# STM32L053x register map
File version: 1.0
Registers are 32-bit, read-write, reset 0x0 unless marked. A register's access mark holds for its fields unless they carry their own. Offsets are from the block's base; [hi:lo] are bit positions; {n}, {i} and the like mark numbered series.

## IWDG — Independent watchdog
Base 0x40003000
0x00 KR wo — Key register
  [15:0] KEY — Key value (write only, read 0x0000)
0x04 PR — Prescaler register
  [2:0] PR — Prescaler divider
0x08 RLR reset 0xFFF — Reload register
  [11:0] RL — Watchdog counter reload value
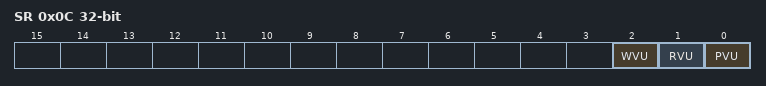
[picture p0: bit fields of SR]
0x0C SR ro — Status register
  [2] WVU — Watchdog counter window value update
  [1] RVU — Watchdog counter reload value update
  [0] PVU — Watchdog prescaler value update
0x10 WINR reset 0xFFF — Window register
  [11:0] WIN — Watchdog counter window value

## WWDG — System window watchdog
Base 0x40002C00
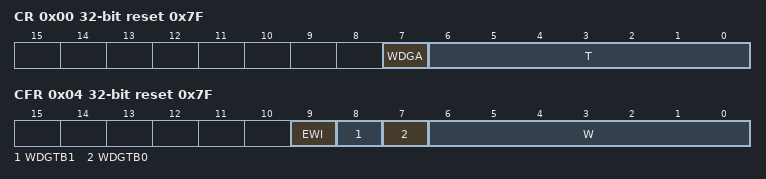
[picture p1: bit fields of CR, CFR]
0x00 CR reset 0x7F — Control register
  [7] WDGA — Activation bit
  [6:0] T — 7-bit counter (MSB to LSB)
0x04 CFR reset 0x7F — Configuration register
  [9] EWI — Early wakeup interrupt
  [8] WDGTB1 — Timer base
  [7] WDGTB0
  [6:0] W — 7-bit window value
0x08 SR rw-once — Status register
  [0] EWIF — Early wakeup interrupt flag

## COMP — Comparator
Base 0x40010018
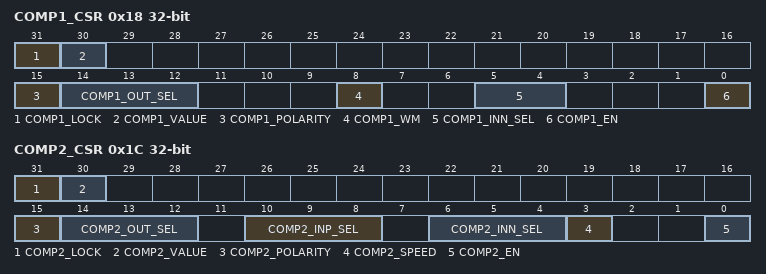
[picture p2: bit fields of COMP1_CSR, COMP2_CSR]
0x18 COMP1_CSR access per field — Comparator 1 control and status register
  [31] COMP1_LOCK wo — COMP1_CSR register lock bit
  [30] COMP1_VALUE ro — Comparator 1 output status bit
  [15] COMP1_POLARITY rw — Comparator 1 polarity selection bit
  [14:12] COMP1_OUT_SEL rw — COMP1 output select
  [8] COMP1_WM rw — Comparator 1 window mode selection bit
  [5:4] COMP1_INN_SEL rw — Comparator 1 Input Minus connection configuration bit
  [0] COMP1_EN rw — Comparator 1 enable bit
0x1C COMP2_CSR access per field — Comparator 2 control and status register
  [31] COMP2_LOCK wo — COMP2_CSR register lock bit
  [30] COMP2_VALUE ro — Comparator 2 output status bit
  [15] COMP2_POLARITY rw — Comparator 2 polarity selection bit
  [14:12] COMP2_OUT_SEL rw — COMP2 output select
  [10:8] COMP2_INP_SEL rw — Comparator 2 Input Plus connection configuration bit
  [6:4] COMP2_INN_SEL rw — Comparator 2 Input Minus connection configuration bit
  [3] COMP2_SPEED rw — Comparator 2 power mode selection bit
  [0] COMP2_EN rw — Comparator 2 enable bit

## USB_FS — Universal serial bus full-speed device interface
Base 0x40005C00
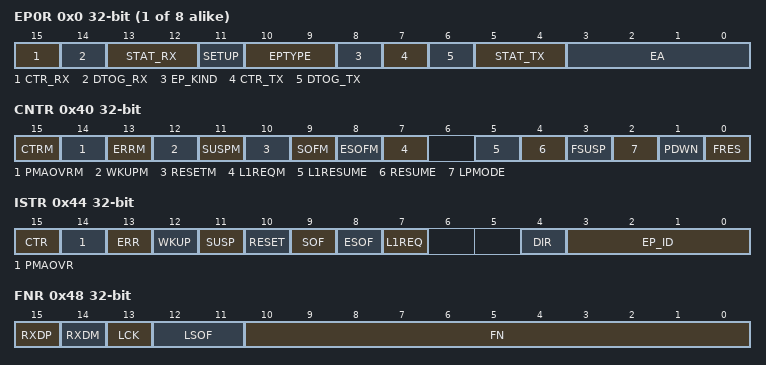
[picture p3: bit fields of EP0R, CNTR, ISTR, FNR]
{0x0+4i} EP{i}R (i=0..7) — endpoint register
  [15] CTR_RX, [14] DTOG_RX, [13:12] STAT_RX, [11] SETUP, [10:9] EPTYPE, [8] EP_KIND, [7] CTR_TX, [6] DTOG_TX, [5:4] STAT_TX, [3:0] EA
0x40 CNTR — control register
  [15] CTRM, [14] PMAOVRM, [13] ERRM, [12] WKUPM, [11] SUSPM, [10] RESETM, [9] SOFM, [8] ESOFM, [7] L1REQM, [5] L1RESUME, [4] RESUME, [3] FSUSP, [2] LPMODE, [1] PDWN, [0] FRES
0x44 ISTR — interrupt status register
  [15] CTR, [14] PMAOVR, [13] ERR, [12] WKUP, [11] SUSP, [10] RESET, [9] SOF, [8] ESOF, [7] L1REQ, [4] DIR, [3:0] EP_ID
0x48 FNR ro — frame number register
  [15] RXDP, [14] RXDM, [13] LCK, [12:11] LSOF, [10:0] FN
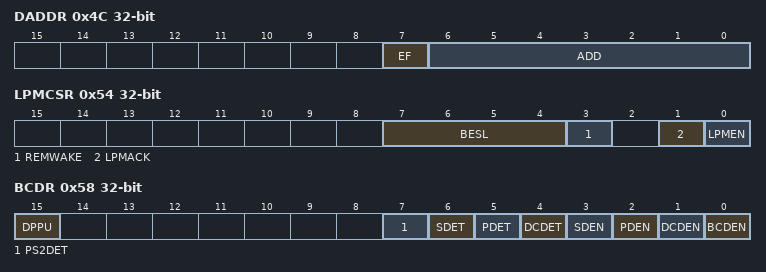
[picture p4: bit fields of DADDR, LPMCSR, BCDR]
0x4C DADDR — device address
  [7] EF, [6:0] ADD
0x50 BTABLE — Buffer table address
  [15:3] BTABLE
0x54 LPMCSR access per field — LPM control and status register
  [7:4] BESL ro, [3] REMWAKE ro, [1] LPMACK rw, [0] LPMEN rw
0x58 BCDR access per field — Battery charging detector
  [15] DPPU rw, [7] PS2DET ro, [6] SDET ro, [5] PDET ro, [4] DCDET ro, [3] SDEN rw, [2] PDEN rw, [1] DCDEN rw, [0] BCDEN rw

## CRS — Clock recovery system
Base 0x40006C00
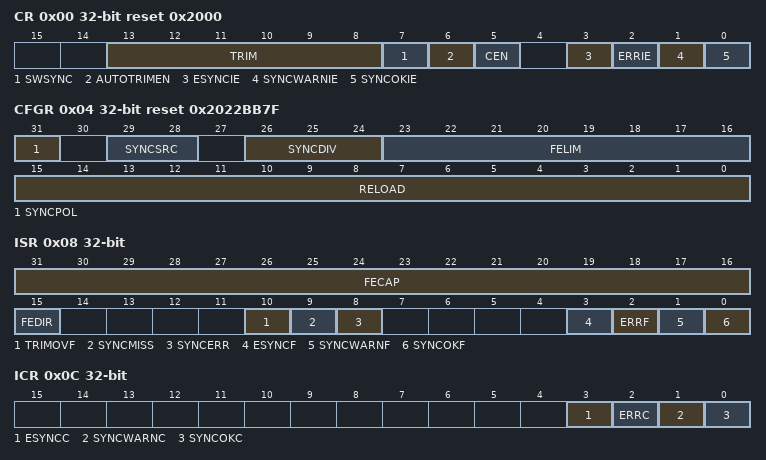
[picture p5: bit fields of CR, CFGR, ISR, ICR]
0x00 CR reset 0x2000 — control register
  [13:8] TRIM — HSI48 oscillator smooth trimming
  [7] SWSYNC — Generate software SYNC event
  [6] AUTOTRIMEN — Automatic trimming enable
  [5] CEN — Frequency error counter enable
  [3] ESYNCIE — Expected SYNC interrupt enable
  [2] ERRIE — Synchronization or trimming error interrupt enable
  [1] SYNCWARNIE — SYNC warning interrupt enable
  [0] SYNCOKIE — SYNC event OK interrupt enable
0x04 CFGR reset 0x2022BB7F — configuration register
  [31] SYNCPOL — SYNC polarity selection
  [29:28] SYNCSRC — SYNC signal source selection
  [26:24] SYNCDIV — SYNC divider
  [23:16] FELIM — Frequency error limit
  [15:0] RELOAD — Counter reload value
0x08 ISR ro — interrupt and status register
  [31:16] FECAP — Frequency error capture
  [15] FEDIR — Frequency error direction
  [10] TRIMOVF — Trimming overflow or underflow
  [9] SYNCMISS — SYNC missed
  [8] SYNCERR — SYNC error
  [3] ESYNCF — Expected SYNC flag
  [2] ERRF — Error flag
  [1] SYNCWARNF — SYNC warning flag
  [0] SYNCOKF — SYNC event OK flag
0x0C ICR — interrupt flag clear register
  [3] ESYNCC — Expected SYNC clear flag
  [2] ERRC — Error clear flag
  [1] SYNCWARNC — SYNC warning clear flag
  [0] SYNCOKC — SYNC event OK clear flag
